VERSION "HIPBNYYYYYYYYYYYYYYYYYYYYYYYYYYYNNNYNNNNNN/4/%%%/4/'%**4NNN///"

NS_ :

BS_:

BU_: Gateway DOOR_ri Console

BO_ 1053 NM_Gateway: 6 Gateway
 SG_ SleepInd : 12|1@1+ (1,0) [0|1] ""  Gateway,DOOR_ri,Console

BO_ 1052 NM_DOORright: 6 DOOR_ri
 SG_ SleepInd : 12|1@1+ (1,0) [0|1] ""  Console,Gateway

BO_ 1050 NM_Console: 6 Console
 SG_ SleepInd : 12|1@1+ (1,0) [0|1] ""  Gateway,DOOR_ri

BO_ 497 DOOR_r: 1 DOOR_ri
 SG_ WN_Position : 0|8@1+ (1,0) [0|100] ""  Gateway,Console

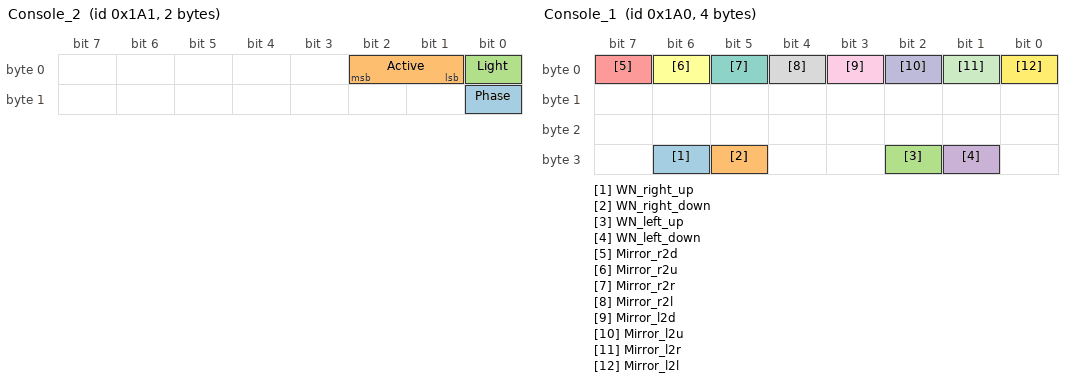
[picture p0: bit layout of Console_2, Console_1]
BO_ 417 Console_2: 2 Console
 SG_ Phase : 8|1@1+ (1,0) [0|1] ""  Gateway
 SG_ Active : 1|2@1+ (1,0) [0|0] ""  Gateway
 SG_ Light : 0|1@1+ (1,0) [0|1] ""  Gateway

BO_ 416 Console_1: 4 Console
 SG_ WN_right_up : 30|1@1+ (1,0) [0|1] ""  Gateway,DOOR_ri
 SG_ WN_right_down : 29|1@1+ (1,0) [0|1] ""  Gateway,DOOR_ri
 SG_ WN_left_up : 26|1@1+ (1,0) [0|1] ""  Gateway
 SG_ WN_left_down : 25|1@1+ (1,0) [0|1] ""  Gateway
 SG_ Mirror_r2d : 7|1@1+ (1,0) [0|1] ""  Gateway
 SG_ Mirror_r2u : 6|1@1+ (1,0) [0|1] ""  Gateway
 SG_ Mirror_r2r : 5|1@1+ (1,0) [0|1] ""  Gateway
 SG_ Mirror_r2l : 4|1@1+ (1,0) [0|1] ""  Gateway
 SG_ Mirror_l2d : 3|1@1+ (1,0) [0|1] ""  Gateway
 SG_ Mirror_l2u : 2|1@1+ (1,0) [0|1] ""  Gateway
 SG_ Mirror_l2r : 1|1@1+ (1,0) [0|1] ""  Gateway
 SG_ Mirror_l2l : 0|1@1+ (1,0) [0|1] ""  Gateway

BO_ 273 Gateway_2: 4 Gateway
 SG_ CarSpeed : 8|16@1+ (0.5,0) [0|300] "km/h"  Console
 SG_ EngineTemp : 0|8@1+ (1,-50) [-50|130] "°C"  Console

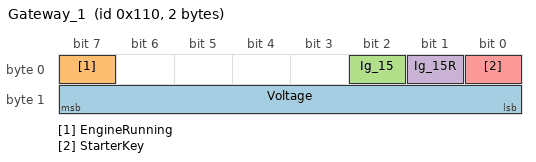
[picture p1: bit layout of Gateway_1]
BO_ 272 Gateway_1: 2 Gateway
 SG_ Voltage : 8|8@1- (1,0) [-128|127] "V" Vector__XXX
 SG_ EngineRunning : 7|1@1+ (1,0) [0|1] "" Vector__XXX
 SG_ Ig_15 : 2|1@1+ (1,0) [0|1] ""  Console
 SG_ Ig_15R : 1|1@1+ (1,0) [0|1] "" Vector__XXX
 SG_ StarterKey : 0|1@1+ (1,0) [0|1] "" Vector__XXX

CM_ "CAN communication matrix for body electronics
*******************************************************

implemented: turn lights, warning lights, windows


";
CM_ BO_ 272 "EZS200

Byte    1: KL_15                Klemmenstatus
        2: Signale              Blinkerschaltung/Hupenkontakt
        3: Wischer              Wisch-/Wasch Schalter
        4: Ubatt                Bordnetzspannung

tz[msec]         tw[msec]          sofort/imZyklus
------------------------------------------------------------
100              -                 sofort



";
BA_DEF_  "BusType" STRING ;
BA_DEF_ BU_  "ILUsed" ENUM  "No","Yes";
BA_DEF_ BO_  "GenMsgILSupport" ENUM  "No","Yes";
BA_DEF_ SG_  "GenSigSendType" ENUM  "Cyclic","OnWrite","OnWriteWithRepetition","OnChange","OnChangeWithRepetition","IfActive","IfActiveWithRepetition";
BA_DEF_ BO_  "GenMsgCycleTime" INT 2 50000;
BA_DEF_ BO_  "GenMsgCycleTimeFast" INT 2 50000;
BA_DEF_ BU_  "NodeLayerModules" STRING ;
BA_DEF_  "NmBaseAddress" HEX 1024 1087;
BA_DEF_ BU_  "NmStationAddress" INT 0 63;
BA_DEF_ BU_  "NmNode" ENUM  "no","yes";
BA_DEF_ BO_  "NmMessage" ENUM  "no","yes";
BA_DEF_ SG_  "NWM-WakeupAllowed" ENUM  "No","Yes";
BA_DEF_  "GenNWMSleepTime" INT 0 1000000;
BA_DEF_DEF_  "BusType" "CAN";
BA_DEF_DEF_  "ILUsed" "Yes";
BA_DEF_DEF_  "GenMsgILSupport" "Yes";
BA_DEF_DEF_  "GenSigSendType" "Cyclic";
BA_DEF_DEF_  "GenMsgCycleTime" 100;
BA_DEF_DEF_  "GenMsgCycleTimeFast" 100;
BA_DEF_DEF_  "NodeLayerModules" "dmoseknm.dll, CANoeILNLVector.dll";
BA_DEF_DEF_  "NmBaseAddress" 1024;
BA_DEF_DEF_  "NmStationAddress" 0;
BA_DEF_DEF_  "NmNode" "no";
BA_DEF_DEF_  "NmMessage" "no";
BA_DEF_DEF_  "NWM-WakeupAllowed" "";
BA_DEF_DEF_  "GenNWMSleepTime" 0;
BA_ "GenNWMSleepTime" 5000;
BA_ "NodeLayerModules" BU_ Gateway "OSEKNM01.dll, CANoeILNLVector.dll";
BA_ "NmStationAddress" BU_ Gateway 29;
BA_ "NmNode" BU_ Gateway 1;
BA_ "NmNode" BU_ DOOR_ri 1;
BA_ "NmStationAddress" BU_ DOOR_ri 28;
BA_ "NodeLayerModules" BU_ DOOR_ri "OSEKNM01.dll, CANoeILNLVector.dll";
BA_ "NmNode" BU_ Console 1;
BA_ "NodeLayerModules" BU_ Console "OSEKNM01.dll, CANoeILNLVector.dll";
BA_ "NmStationAddress" BU_ Console 26;
BA_ "GenMsgILSupport" BO_ 1053 0;
BA_ "NmMessage" BO_ 1053 1;
BA_ "GenMsgILSupport" BO_ 1052 0;
BA_ "NmMessage" BO_ 1052 1;
BA_ "GenMsgILSupport" BO_ 1050 0;
BA_ "NmMessage" BO_ 1050 1;
BA_ "NWM-WakeupAllowed" SG_ 1053 SleepInd 1;
BA_ "NWM-WakeupAllowed" SG_ 1052 SleepInd 1;
BA_ "NWM-WakeupAllowed" SG_ 1050 SleepInd 1;
BA_ "GenSigSendType" SG_ 497 WN_Position 3;
BA_ "NWM-WakeupAllowed" SG_ 497 WN_Position 1;
BA_ "GenSigSendType" SG_ 417 Phase 5;
BA_ "NWM-WakeupAllowed" SG_ 417 Phase 1;
BA_ "GenSigSendType" SG_ 417 Active 5;
BA_ "NWM-WakeupAllowed" SG_ 417 Active 1;
BA_ "GenSigSendType" SG_ 417 Light 5;
BA_ "NWM-WakeupAllowed" SG_ 417 Light 1;
BA_ "GenSigSendType" SG_ 416 WN_right_up 5;
BA_ "NWM-WakeupAllowed" SG_ 416 WN_right_up 1;
BA_ "GenSigSendType" SG_ 416 WN_right_down 5;
BA_ "NWM-WakeupAllowed" SG_ 416 WN_right_down 1;
BA_ "GenSigSendType" SG_ 416 WN_left_up 5;
BA_ "NWM-WakeupAllowed" SG_ 416 WN_left_up 1;
BA_ "GenSigSendType" SG_ 416 WN_left_down 5;
BA_ "NWM-WakeupAllowed" SG_ 416 WN_left_down 1;
BA_ "GenSigSendType" SG_ 416 Mirror_r2d 5;
BA_ "NWM-WakeupAllowed" SG_ 416 Mirror_r2d 1;
BA_ "GenSigSendType" SG_ 416 Mirror_r2u 5;
BA_ "NWM-WakeupAllowed" SG_ 416 Mirror_r2u 1;
BA_ "GenSigSendType" SG_ 416 Mirror_r2r 5;
BA_ "NWM-WakeupAllowed" SG_ 416 Mirror_r2r 1;
BA_ "GenSigSendType" SG_ 416 Mirror_r2l 5;
BA_ "NWM-WakeupAllowed" SG_ 416 Mirror_r2l 1;
BA_ "GenSigSendType" SG_ 416 Mirror_l2d 5;
BA_ "NWM-WakeupAllowed" SG_ 416 Mirror_l2d 1;
BA_ "GenSigSendType" SG_ 416 Mirror_l2u 5;
BA_ "NWM-WakeupAllowed" SG_ 416 Mirror_l2u 1;
BA_ "GenSigSendType" SG_ 416 Mirror_l2r 5;
BA_ "NWM-WakeupAllowed" SG_ 416 Mirror_l2r 1;
BA_ "GenSigSendType" SG_ 416 Mirror_l2l 5;
BA_ "NWM-WakeupAllowed" SG_ 416 Mirror_l2l 1;
BA_ "GenSigSendType" SG_ 273 CarSpeed 1;
BA_ "NWM-WakeupAllowed" SG_ 273 CarSpeed 1;
BA_ "GenSigSendType" SG_ 273 EngineTemp 1;
BA_ "NWM-WakeupAllowed" SG_ 273 EngineTemp 1;
BA_ "NWM-WakeupAllowed" SG_ 272 Voltage 1;
BA_ "NWM-WakeupAllowed" SG_ 272 EngineRunning 1;
BA_ "NWM-WakeupAllowed" SG_ 272 Ig_15 1;
BA_ "NWM-WakeupAllowed" SG_ 272 Ig_15R 1;
BA_ "NWM-WakeupAllowed" SG_ 272 StarterKey 1;
VAL_ 417 Active 0 "None" 1 "Turn_right" 2 "Turn_left" 3 "Warning" ;
